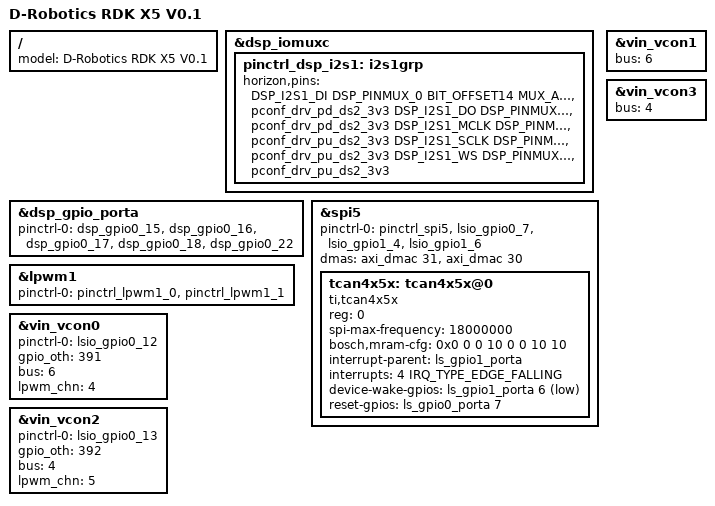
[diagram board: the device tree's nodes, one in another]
// SPDX-License-Identifier: GPL-2.0
/*
 * dts for Sunrise5 EVB-V2 platform
 *
 * Copyright (C) 2024 Horizon Robotics Inc.
 *
 */

/dts-v1/;
#include "x5-rdk.dtsi"

/ {
	model = "D-Robotics RDK X5 V0.1";
};

&dsp_iomuxc {
	pinctrl_dsp_i2s1: i2s1grp {
		horizon,pins = <
			DSP_I2S1_DI  DSP_PINMUX_0  BIT_OFFSET14  MUX_ALT0 &pconf_drv_pd_ds2_3v3
			DSP_I2S1_DO  DSP_PINMUX_0  BIT_OFFSET16  MUX_ALT0 &pconf_drv_pd_ds2_3v3
			DSP_I2S1_MCLK  DSP_PINMUX_0  BIT_OFFSET18  MUX_ALT0 &pconf_drv_pu_ds2_3v3
			DSP_I2S1_SCLK  DSP_PINMUX_0  BIT_OFFSET20  MUX_ALT0 &pconf_drv_pu_ds2_3v3
			DSP_I2S1_WS  DSP_PINMUX_0  BIT_OFFSET22  MUX_ALT0 &pconf_drv_pu_ds2_3v3
		>;
	};
};

//wifi antenna Onboard
&dsp_gpio_porta {
	pinctrl-names = "default";
	pinctrl-0 = < &dsp_gpio0_15
				  &dsp_gpio0_16
				  &dsp_gpio0_17
				  &dsp_gpio0_18
				  &dsp_gpio0_22 //USB HUB RESET high
				>;
};

&spi5 {
	status = "okay";
	pinctrl-names = "default";
	pinctrl-0 = <&pinctrl_spi5 &lsio_gpio0_7 &lsio_gpio1_4 &lsio_gpio1_6>;
	dma-names = "tx", "rx";
	dmas = <&axi_dmac 31>, <&axi_dmac 30>;

	tcan4x5x: tcan4x5x@0 {
		compatible = "ti,tcan4x5x";
		reg = <0>;
		#address-cells = <1>;
		#size-cells = <1>;
		spi-max-frequency = <18000000>;
		bosch,mram-cfg = <0x0 0 0 10 0 0 10 10>;
		interrupt-parent = <&ls_gpio1_porta>;
		interrupts = <4 IRQ_TYPE_EDGE_FALLING>;
		device-wake-gpios = <&ls_gpio1_porta 6 GPIO_ACTIVE_LOW>;
		reset-gpios = <&ls_gpio0_porta 7 GPIO_ACTIVE_HIGH>;
	};
};

&lpwm1 {
	status = "okay";
	pinctrl-names = "default";
	/** for display backlight **/
	pinctrl-0 = <&pinctrl_lpwm1_0 &pinctrl_lpwm1_1>;
};

&vin_vcon0 {
	status = "okay";
	/* camera sensor
	 * reset gpio:	LSIO_GPIO0_PIN12:	391
	 * lpwm      :  LSIO_SPI3_SCLK  :   pinctrl_lpwm1_0
	 */
	pinctrl-names = "default";
	pinctrl-0 = <&lsio_gpio0_12>;
	gpio_oth = <391>;   // reset gpio
	bus = <6>; // i2c bus
	lpwm_chn = <4>;
};

&vin_vcon1 {
	status = "okay";
	// use same sensor gpio with vcon0 and i2c bus
	bus = <6>;
};

&vin_vcon2 {
	status = "okay";
	/* camera sensor
	 * reset gpio:	LSIO_GPIO0_PIN13:	392
	 * lpwm      :  LSIO_SPI3_SSN  :    pinctrl_lpwm1_1
	 */
	pinctrl-names = "default";
	pinctrl-0 = <&lsio_gpio0_13>;
	gpio_oth = <392>;   // reset gpio
	bus = <4>;  // i2c bus
	lpwm_chn = <5>;
};

&vin_vcon3 {
	status = "okay";
	// use same sensor gpio with vcon2 and i2c bus
	bus = <4>;
};
